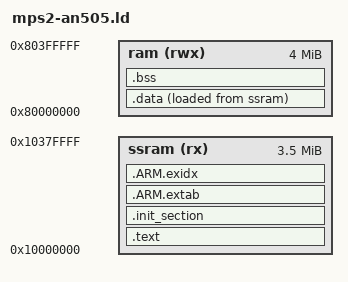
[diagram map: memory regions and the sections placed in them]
/****************************************************************************
 *
 * Copyright 2026 Samsung Electronics All Rights Reserved.
 *
 * Licensed under the Apache License, Version 2.0 (the "License");
 * you may not use this file except in compliance with the License.
 * You may obtain a copy of the License at
 *
 * http://www.apache.org/licenses/LICENSE-2.0
 *
 * Unless required by applicable law or agreed to in writing, software
 * distributed under the License is distributed on an "AS IS" BASIS,
 * WITHOUT WARRANTIES OR CONDITIONS OF ANY KIND, either express or implied.
 * See the License for the specific language governing permissions and
 * limitations under the License.
 *
 ****************************************************************************/

MEMORY
{
	/* Keep 512 KiB of SSRAM for the secondary heap. */
	ssram (rx)  : ORIGIN = 0x10000000, LENGTH = 0x380000
	/* The upper 12 MiB of main RAM is managed as heap regions. */
	ram   (rwx) : ORIGIN = 0x80000000, LENGTH = 4M
}

OUTPUT_ARCH(arm)
ENTRY(_stext_flash)
SECTIONS
{
	.text : {
		_stext_flash = ABSOLUTE(.);
		*(.vectors)
		*(.text .text.*)
		*(.fixup)
		*(.gnu.warning)
		*(.rodata .rodata.*)
		*(.gnu.linkonce.t.*)
		*(.glue_7)
		*(.glue_7t)
		*(.got)
		*(.gcc_except_table)
		*(.gnu.linkonce.r.*)
		_etext_flash = ABSOLUTE(.);
	} > ssram

	.init_section : {
		_sinit = ABSOLUTE(.);
		*(.init_array .init_array.*)
		_einit = ABSOLUTE(.);
	} > ssram

	.ARM.extab : {
		*(.ARM.extab*)
	} > ssram

	__exidx_start = ABSOLUTE(.);
	.ARM.exidx : {
		*(.ARM.exidx*)
	} > ssram
	__exidx_end = ABSOLUTE(.);

	_eronly = LOADADDR(.data);

	.data : {
		_sdata = ABSOLUTE(.);
		*(.data .data.*)
		*(.gnu.linkonce.d.*)
		CONSTRUCTORS
		_edata = ABSOLUTE(.);
	} > ram AT > ssram

	.bss : {
		_sbss = ABSOLUTE(.);
		*(.bss .bss.*)
		*(.gnu.linkonce.b.*)
		*(COMMON)
		_ebss = ABSOLUTE(.);
		_sidle_stack = ABSOLUTE(.);
		. = . + CONFIG_IDLETHREAD_STACKSIZE;
		_sint_heap = ABSOLUTE(.);
	} > ram

	.stab 0 : { *(.stab) }
	.stabstr 0 : { *(.stabstr) }
	.stab.excl 0 : { *(.stab.excl) }
	.stab.exclstr 0 : { *(.stab.exclstr) }
	.stab.index 0 : { *(.stab.index) }
	.stab.indexstr 0 : { *(.stab.indexstr) }
	.comment 0 : { *(.comment) }
	.debug_abbrev 0 : { *(.debug_abbrev) }
	.debug_info 0 : { *(.debug_info) }
	.debug_line 0 : { *(.debug_line) }
	.debug_pubnames 0 : { *(.debug_pubnames) }
	.debug_aranges 0 : { *(.debug_aranges) }
}
